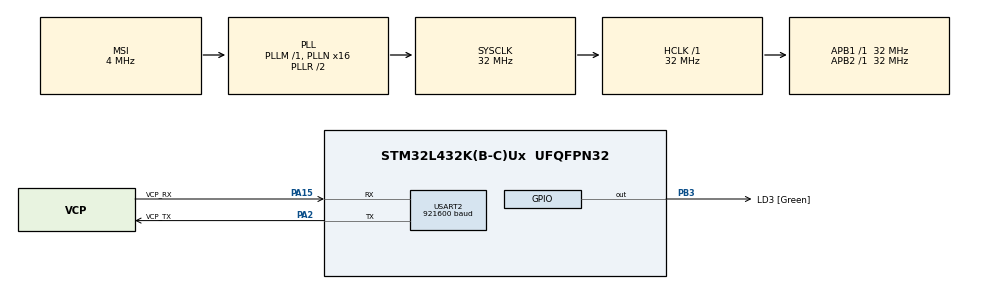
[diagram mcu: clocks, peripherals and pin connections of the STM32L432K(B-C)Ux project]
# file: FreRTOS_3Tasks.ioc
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FREERTOS.Queues01=myQueueA,16,uint16_t,0,Dynamic,NULL,NULL;myQueueB,16,uint16_t,0,Dynamic,NULL,NULL;myQueueC,16,uint16_t,0,Dynamic,NULL,NULL
FREERTOS.Tasks01=defaultTask,8,128,StartDefaultTask,Default,NULL,Dynamic,NULL,NULL;myTaskA,40,128,StartTaskA,Default,NULL,Dynamic,NULL,NULL;myTaskB,32,128,StartTaskB,Default,NULL,Dynamic,NULL,NULL;myTaskC,24,128,StartTaskC,Default,NULL,Dynamic,NULL,NULL
FREERTOS.configTOTAL_HEAP_SIZE=6000
FREERTOS.configUSE_NEWLIB_REENTRANT=1
Mcu.Family=STM32L4
Mcu.Name=STM32L432K(B-C)Ux
Mcu.Package=UFQFPN32
NVIC.PriorityGroup=NVIC_PRIORITYGROUP_4
NVIC.TIM1_BRK_TIM15_IRQn=true\:5\:0\:false\:false\:true\:true\:true\:true\:true
NVIC.TIM1_UP_TIM16_IRQn=true\:5\:0\:false\:false\:true\:true\:true\:true\:true
NVIC.TIM6_DAC_IRQn=true\:15\:0\:false\:false\:true\:false\:false\:true\:true
NVIC.TimeBase=TIM6_DAC_IRQn
NVIC.TimeBaseIP=TIM6
PA0.GPIO_Label=MCO [High speed clock in]
PA0.Mode=HSE-External-Clock-Source-for-LittleOrca
PA0.Signal=RCC_CK_IN
PA13\ (JTMS-SWDIO).GPIO_Label=SWDIO
PA13\ (JTMS-SWDIO).Mode=Serial_Wire
PA13\ (JTMS-SWDIO).Signal=SYS_JTMS-SWDIO
PA14\ (JTCK-SWCLK).GPIO_Label=SWCLK
PA14\ (JTCK-SWCLK).Mode=Serial_Wire
PA14\ (JTCK-SWCLK).Signal=SYS_JTCK-SWCLK
PA15\ (JTDI).GPIO_Label=VCP_RX
PA15\ (JTDI).Mode=Asynchronous
PA15\ (JTDI).Signal=USART2_RX
PA2.GPIO_Label=VCP_TX
PA2.Mode=Asynchronous
PA2.Signal=USART2_TX
PB3\ (JTDO-TRACESWO).GPIO_Label=LD3 [Green]
PB3\ (JTDO-TRACESWO).Signal=GPIO_Output
PC14-OSC32_IN\ (PC14).Mode=LSE-External-Oscillator
PC14-OSC32_IN\ (PC14).Signal=RCC_OSC32_IN
PC15-OSC32_OUT\ (PC15).Mode=LSE-External-Oscillator
PC15-OSC32_OUT\ (PC15).Signal=RCC_OSC32_OUT
ProjectManager.HeapSize=0x200
ProjectManager.StackSize=0x400
ProjectManager.TargetToolchain=CMake
RCC.AHBFreq_Value=32000000
RCC.APB1Freq_Value=32000000
RCC.APB1TimFreq_Value=32000000
RCC.APB2Freq_Value=32000000
RCC.APB2TimFreq_Value=32000000
RCC.CortexFreq_Value=32000000
RCC.HCLKFreq_Value=32000000
RCC.HSE_VALUE=8000000
RCC.HSI16_VALUE=16000000
RCC.HSI48_VALUE=48000000
RCC.HSI_VALUE=16000000
RCC.MSI_VALUE=4000000
RCC.PLLMUL=RCC_PLLMUL_4
RCC.PLLN=16
RCC.SYSCLKFreq_VALUE=32000000
RCC.SYSCLKSource=RCC_SYSCLKSOURCE_PLLCLK
RCC.VCOOutputFreq_Value=64000000
TIM1.Period=100-1
TIM1.Prescaler=32000-1
TIM1.RepetitionCounter=0
TIM15.Period=150-1
TIM15.Prescaler=32000-1
TIM16.Period=350-1
TIM16.Prescaler=32000-1
TIM2.Prescaler=32-1
USART2.BaudRate=921600
USART2.VirtualMode-Asynchronous=VM_ASYNC
VP_FREERTOS_VS_CMSIS_V2.Mode=CMSIS_V2
VP_SYS_VS_tim6.Mode=TIM6
VP_TIM15_VS_ClockSourceINT.Mode=Internal
VP_TIM16_VS_ClockSourceINT.Mode=Enable_Timer
VP_TIM1_VS_ClockSourceINT.Mode=Internal
VP_TIM2_VS_ClockSourceINT.Mode=Internal
board=NUCLEO-L432KC

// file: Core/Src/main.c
/* USER CODE BEGIN Header */
/**
  ******************************************************************************
  * @file           : main.c
  * @brief          : Main program body
  ******************************************************************************
  * @attention
  *
  * Copyright (c) 2023 STMicroelectronics.
  * All rights reserved.
  *
  * This software is licensed under terms that can be found in the LICENSE file
  * in the root directory of this software component.
  * If no LICENSE file comes with this software, it is provided AS-IS.
  *
  ******************************************************************************
  */
/* USER CODE END Header */
#include "main.h"
#include "cmsis_os.h"

/* USER CODE BEGIN Includes */
#include <stdio.h>
#include "tracer.h"
#include "config/tracer_config.h"
/* USER CODE END Includes */

TIM_HandleTypeDef htim1;
TIM_HandleTypeDef htim2;
TIM_HandleTypeDef htim15;
TIM_HandleTypeDef htim16;

UART_HandleTypeDef huart2;

/* Definitions for defaultTask */
osThreadId_t defaultTaskHandle;
const osThreadAttr_t defaultTask_attributes = {
  .name = "defaultTask",
  .stack_size = 128 * 4,
  .priority = (osPriority_t) osPriorityLow,
};
/* Definitions for myTaskA */
osThreadId_t myTaskAHandle;
const osThreadAttr_t myTaskA_attributes = {
  .name = "myTaskA",
  .stack_size = 128 * 4,
  .priority = (osPriority_t) osPriorityHigh,
};
/* Definitions for myTaskB */
osThreadId_t myTaskBHandle;
const osThreadAttr_t myTaskB_attributes = {
  .name = "myTaskB",
  .stack_size = 128 * 4,
  .priority = (osPriority_t) osPriorityAboveNormal,
};
/* Definitions for myTaskC */
osThreadId_t myTaskCHandle;
const osThreadAttr_t myTaskC_attributes = {
  .name = "myTaskC",
  .stack_size = 128 * 4,
  .priority = (osPriority_t) osPriorityNormal,
};
/* Definitions for myQueueA */
osMessageQueueId_t myQueueAHandle;
const osMessageQueueAttr_t myQueueA_attributes = {
  .name = "myQueueA"
};
/* Definitions for myQueueB */
osMessageQueueId_t myQueueBHandle;
const osMessageQueueAttr_t myQueueB_attributes = {
  .name = "myQueueB"
};
/* Definitions for myQueueC */
osMessageQueueId_t myQueueCHandle;
const osMessageQueueAttr_t myQueueC_attributes = {
  .name = "myQueueC"
};
/* USER CODE BEGIN PV */
// Buffer for UART
uint8_t uart_rx_buffer[32];
volatile uint8_t uart_rx_index = 0;

// Tracer task variables
osThreadId_t tracerTaskHandle;
const osThreadAttr_t tracerTask_attributes = {
  .name = "tracerTask",
  .stack_size = 128 * 4,
  .priority = (osPriority_t) osPriorityLow,
};
/* USER CODE END PV */

void SystemClock_Config(void);
static void MX_GPIO_Init(void);
static void MX_USART2_UART_Init(void);
static void MX_TIM1_Init(void);
static void MX_TIM15_Init(void);
static void MX_TIM16_Init(void);
static void MX_TIM2_Init(void);
void StartDefaultTask(void *argument);
void StartTaskA(void *argument);
void StartTaskB(void *argument);
void StartTaskC(void *argument);

/* USER CODE BEGIN 0 */
int __io_putchar(int ch) {
	while( !(USART2->ISR & USART_ISR_TXE) );
	USART2->TDR = ch;
	return ch;
}

/**
 * @brief Start UART reception in interrupt mode
 * Call this during initialization to enable command processing
 * @param None
 * @retval None
 */
void start_uart_reception(void) {
  #if MAIN_DEBUG
    const char* msg = "UART reception initialized\r\n";
    HAL_UART_Transmit(&huart2, (uint8_t*)msg, strlen(msg), HAL_MAX_DELAY);
  #endif

  HAL_UART_Receive_IT(&huart2, &uart_rx_buffer[uart_rx_index], 1);

  #if MAIN_DEBUG
    const char* msg1 = "UART receive started\r\n";
    HAL_UART_Transmit(&huart2, (uint8_t*)msg1, strlen(msg1), HAL_MAX_DELAY);
  #endif
}

/**
 * @brief Process received UART commands
 * - "DUMP" - Save trace data to flash
 * - "GET" - Retrieve trace data from flash
 */
void process_uart_command(void) {
  uart_rx_buffer[uart_rx_index] = '\0';

  #if MAIN_DEBUG
    // For debugging
    char debug_msg[50];
    snprintf(debug_msg, sizeof(debug_msg), "Received command: %s\r\n", uart_rx_buffer);
    HAL_UART_Transmit(&huart2, (uint8_t*)debug_msg, strlen(debug_msg), HAL_MAX_DELAY);
  #endif

  if (strncmp((char*)uart_rx_buffer, "TEST", 4) == 0) {
      #if MAIN_DEBUG
        const char* msg = "TEST command received successfully\r\n";
        HAL_UART_Transmit(&huart2, (uint8_t*)msg, strlen(msg), HAL_MAX_DELAY);
      #endif
  }
  // Dump command - force immediate send of trace data
  else if (strncmp((char*)uart_rx_buffer, "DUMP", 4) == 0) {
    #if MAIN_DEBUG
      const char* msg = "DUMP command: Sending all pending trace events\r\n";
      HAL_UART_Transmit(&huart2, (uint8_t*)msg, strlen(msg), HAL_MAX_DELAY);
    #endif

    tracer_send_events();
  }
  // Status command
  else if (strncmp((char*)uart_rx_buffer, "STATUS", 6) == 0) {
    #if MAIN_DEBUG
      char status_msg[150];
      snprintf(status_msg, sizeof(status_msg),
      "Trace status:\r\n"
      "Events in buffer: %lu/%d\r\n"
      "Hook calls: %lu\r\n"
      "Events sent: %lu\r\n",
      trace_count, TRACE_BUFFER_SIZE,
      trace_hook_calls, sent_events);
      HAL_UART_Transmit(&huart2, (uint8_t*)status_msg, strlen(status_msg), HAL_MAX_DELAY);
    #endif
  }

  uart_rx_index = 0;
}

/**
* @brief Function implementing the tracerTask thread.
* @param argument: Not used
* @retval None
*/
void StartTracerTask(void *argument) {
     // Small delay to let system initialize
    osDelay(500);

    #if MAIN_DEBUG
      const char* msg = "\r\n----- TRACER STARTING -----\r\n";
      HAL_UART_Transmit(&huart2, (uint8_t*)msg, strlen(msg), HAL_MAX_DELAY);

      char debug[100];
      snprintf(debug, sizeof(debug), "Tracer config: Buffer size=%d, Event size=%lu bytes\r\n",
               TRACE_BUFFER_SIZE, sizeof(trace_event_t));
      HAL_UART_Transmit(&huart2, (uint8_t*)debug, strlen(debug), HAL_MAX_DELAY);
    #endif

    // Initialize the tracer
    tracer_init();

    // Debug buffer status
    tracer_debug_buffer();

    #if MAIN_DEBUG
      // Manually log some events
      tracer_log(TRACE_EVENT_TI, 0xBEEF, NULL);
      tracer_log(TRACE_EVENT_TO, 0xBEEF, NULL);

      snprintf(debug, sizeof(debug), "Added test events. Count now: %lu\r\n", trace_count);
      HAL_UART_Transmit(&huart2, (uint8_t*)debug, strlen(debug), HAL_MAX_DELAY);

      // Clear separator before binary data starts
      msg = "\r\n----- BINARY DATA FOLLOWS -----\r\n";
      HAL_UART_Transmit(&huart2, (uint8_t*)msg, strlen(msg), HAL_MAX_DELAY);
    #endif

    tracer_send_events();

    // Main loop
    uint32_t iteration = 0;
    for(;;) {
        iteration++;

        // Process trace data - this will handle sending events
        tracer_process();

        // Every 50 iterations, force a dump all events
        if (iteration % 50 == 0) {
            #if MAIN_DEBUG
                snprintf(debug, sizeof(debug), "Forcing event dump. Count: %lu\r\n", trace_count);
                HAL_UART_Transmit(&huart2, (uint8_t*)debug, strlen(debug), HAL_MAX_DELAY);
            #endif

            tracer_send_events();
        }

        // Delay 10ms between processing cycles
        osDelay(10);
    }
}

#pragma GCC push_options
#pragma GCC optimize("O3")
void busy(uint32_t us) {
	while(us-- > 0) {
		asm("nop; nop; nop; nop;    nop; nop; nop; nop; ");
		asm("nop; nop; nop; nop;    nop; nop; nop; nop; ");
		asm("nop; nop; nop; nop;    nop; nop; nop; nop; ");
		asm("nop; nop; nop; nop;    nop;                ");
	}
}
#pragma GCC pop_options
/* USER CODE END 0 */

int main(void)
{

  /* MCU Configuration--------------------------------------------------------*/

  /* Reset of all peripherals, Initializes the Flash interface and the Systick. */
  HAL_Init();

  /* Configure the system clock */
  SystemClock_Config();

  /* Initialize all configured peripherals */
  MX_GPIO_Init();
  MX_USART2_UART_Init();
  MX_TIM1_Init();
  MX_TIM15_Init();
  MX_TIM16_Init();
  MX_TIM2_Init();
  /* USER CODE BEGIN 2 */

  HAL_TIM_Base_Start(&htim2);
  start_uart_reception();
  /* USER CODE END 2 */

  /* Init scheduler */
  osKernelInitialize();

  /* Create the queue(s) */
  /* creation of myQueueA */
  myQueueAHandle = osMessageQueueNew (16, sizeof(uint16_t), &myQueueA_attributes);

  /* creation of myQueueB */
  myQueueBHandle = osMessageQueueNew (16, sizeof(uint16_t), &myQueueB_attributes);

  /* creation of myQueueC */
  myQueueCHandle = osMessageQueueNew (16, sizeof(uint16_t), &myQueueC_attributes);

  /* Create the thread(s) */
  /* creation of defaultTask */
  defaultTaskHandle = osThreadNew(StartDefaultTask, NULL, &defaultTask_attributes);

  /* creation of myTaskA */
  myTaskAHandle = osThreadNew(StartTaskA, NULL, &myTaskA_attributes);

  /* creation of myTaskB */
  myTaskBHandle = osThreadNew(StartTaskB, NULL, &myTaskB_attributes);

  /* creation of myTaskC */
  myTaskCHandle = osThreadNew(StartTaskC, NULL, &myTaskC_attributes);

  /* USER CODE BEGIN RTOS_THREADS */
  /* add threads, ... */
  tracerTaskHandle = osThreadNew(StartTracerTask, NULL, &tracerTask_attributes);
  if (tracerTaskHandle == NULL) {
    Error_Handler();
  }
  /* USER CODE END RTOS_THREADS */

  /* Start scheduler */
  osKernelStart();

  /* We should never get here as control is now taken by the scheduler */

  /* Infinite loop */
  while (1)
  {

  }
}

void SystemClock_Config(void)
{
  RCC_OscInitTypeDef RCC_OscInitStruct = {0};
  RCC_ClkInitTypeDef RCC_ClkInitStruct = {0};

  /** Configure the main internal regulator output voltage
  */
  if (HAL_PWREx_ControlVoltageScaling(PWR_REGULATOR_VOLTAGE_SCALE1) != HAL_OK)
  {
    Error_Handler();
  }

  /** Configure LSE Drive Capability
  */
  HAL_PWR_EnableBkUpAccess();
  __HAL_RCC_LSEDRIVE_CONFIG(RCC_LSEDRIVE_LOW);

  /** Initializes the RCC Oscillators according to the specified parameters
  * in the RCC_OscInitTypeDef structure.
  */
  RCC_OscInitStruct.OscillatorType = RCC_OSCILLATORTYPE_LSE|RCC_OSCILLATORTYPE_MSI;
  RCC_OscInitStruct.LSEState = RCC_LSE_ON;
  RCC_OscInitStruct.MSIState = RCC_MSI_ON;
  RCC_OscInitStruct.MSICalibrationValue = 0;
  RCC_OscInitStruct.MSIClockRange = RCC_MSIRANGE_6;
  RCC_OscInitStruct.PLL.PLLState = RCC_PLL_ON;
  RCC_OscInitStruct.PLL.PLLSource = RCC_PLLSOURCE_MSI;
  RCC_OscInitStruct.PLL.PLLM = 1;
  RCC_OscInitStruct.PLL.PLLN = 16;
  RCC_OscInitStruct.PLL.PLLP = RCC_PLLP_DIV7;
  RCC_OscInitStruct.PLL.PLLQ = RCC_PLLQ_DIV2;
  RCC_OscInitStruct.PLL.PLLR = RCC_PLLR_DIV2;
  if (HAL_RCC_OscConfig(&RCC_OscInitStruct) != HAL_OK)
  {
    Error_Handler();
  }

  /** Initializes the CPU, AHB and APB buses clocks
  */
  RCC_ClkInitStruct.ClockType = RCC_CLOCKTYPE_HCLK|RCC_CLOCKTYPE_SYSCLK
                              |RCC_CLOCKTYPE_PCLK1|RCC_CLOCKTYPE_PCLK2;
  RCC_ClkInitStruct.SYSCLKSource = RCC_SYSCLKSOURCE_PLLCLK;
  RCC_ClkInitStruct.AHBCLKDivider = RCC_SYSCLK_DIV1;
  RCC_ClkInitStruct.APB1CLKDivider = RCC_HCLK_DIV1;
  RCC_ClkInitStruct.APB2CLKDivider = RCC_HCLK_DIV1;

  if (HAL_RCC_ClockConfig(&RCC_ClkInitStruct, FLASH_LATENCY_1) != HAL_OK)
  {
    Error_Handler();
  }

  /** Enable MSI Auto calibration
  */
  HAL_RCCEx_EnableMSIPLLMode();
}

static void MX_TIM1_Init(void)
{

  TIM_ClockConfigTypeDef sClockSourceConfig = {0};
  TIM_MasterConfigTypeDef sMasterConfig = {0};

  htim1.Instance = TIM1;
  htim1.Init.Prescaler = 32000-1;
  htim1.Init.CounterMode = TIM_COUNTERMODE_UP;
  htim1.Init.Period = 100-1;
  htim1.Init.ClockDivision = TIM_CLOCKDIVISION_DIV1;
  htim1.Init.RepetitionCounter = 0;
  htim1.Init.AutoReloadPreload = TIM_AUTORELOAD_PRELOAD_DISABLE;
  if (HAL_TIM_Base_Init(&htim1) != HAL_OK)
  {
    Error_Handler();
  }
  sClockSourceConfig.ClockSource = TIM_CLOCKSOURCE_INTERNAL;
  if (HAL_TIM_ConfigClockSource(&htim1, &sClockSourceConfig) != HAL_OK)
  {
    Error_Handler();
  }
  sMasterConfig.MasterOutputTrigger = TIM_TRGO_RESET;
  sMasterConfig.MasterOutputTrigger2 = TIM_TRGO2_RESET;
  sMasterConfig.MasterSlaveMode = TIM_MASTERSLAVEMODE_DISABLE;
  if (HAL_TIMEx_MasterConfigSynchronization(&htim1, &sMasterConfig) != HAL_OK)
  {
    Error_Handler();
  }

}

static void MX_TIM2_Init(void)
{

  TIM_ClockConfigTypeDef sClockSourceConfig = {0};
  TIM_MasterConfigTypeDef sMasterConfig = {0};

  htim2.Instance = TIM2;
  htim2.Init.Prescaler = 32-1;
  htim2.Init.CounterMode = TIM_COUNTERMODE_UP;
  htim2.Init.Period = 4294967295;
  htim2.Init.ClockDivision = TIM_CLOCKDIVISION_DIV1;
  htim2.Init.AutoReloadPreload = TIM_AUTORELOAD_PRELOAD_DISABLE;
  if (HAL_TIM_Base_Init(&htim2) != HAL_OK)
  {
    Error_Handler();
  }
  sClockSourceConfig.ClockSource = TIM_CLOCKSOURCE_INTERNAL;
  if (HAL_TIM_ConfigClockSource(&htim2, &sClockSourceConfig) != HAL_OK)
  {
    Error_Handler();
  }
  sMasterConfig.MasterOutputTrigger = TIM_TRGO_RESET;
  sMasterConfig.MasterSlaveMode = TIM_MASTERSLAVEMODE_DISABLE;
  if (HAL_TIMEx_MasterConfigSynchronization(&htim2, &sMasterConfig) != HAL_OK)
  {
    Error_Handler();
  }

}

static void MX_TIM15_Init(void)
{

  TIM_ClockConfigTypeDef sClockSourceConfig = {0};
  TIM_MasterConfigTypeDef sMasterConfig = {0};

  htim15.Instance = TIM15;
  htim15.Init.Prescaler = 32000-1;
  htim15.Init.CounterMode = TIM_COUNTERMODE_UP;
  htim15.Init.Period = 150-1;
  htim15.Init.ClockDivision = TIM_CLOCKDIVISION_DIV1;
  htim15.Init.RepetitionCounter = 0;
  htim15.Init.AutoReloadPreload = TIM_AUTORELOAD_PRELOAD_DISABLE;
  if (HAL_TIM_Base_Init(&htim15) != HAL_OK)
  {
    Error_Handler();
  }
  sClockSourceConfig.ClockSource = TIM_CLOCKSOURCE_INTERNAL;
  if (HAL_TIM_ConfigClockSource(&htim15, &sClockSourceConfig) != HAL_OK)
  {
    Error_Handler();
  }
  sMasterConfig.MasterOutputTrigger = TIM_TRGO_RESET;
  sMasterConfig.MasterSlaveMode = TIM_MASTERSLAVEMODE_DISABLE;
  if (HAL_TIMEx_MasterConfigSynchronization(&htim15, &sMasterConfig) != HAL_OK)
  {
    Error_Handler();
  }

}

static void MX_TIM16_Init(void)
{

  htim16.Instance = TIM16;
  htim16.Init.Prescaler = 32000-1;
  htim16.Init.CounterMode = TIM_COUNTERMODE_UP;
  htim16.Init.Period = 350-1;
  htim16.Init.ClockDivision = TIM_CLOCKDIVISION_DIV1;
  htim16.Init.RepetitionCounter = 0;
  htim16.Init.AutoReloadPreload = TIM_AUTORELOAD_PRELOAD_DISABLE;
  if (HAL_TIM_Base_Init(&htim16) != HAL_OK)
  {
    Error_Handler();
  }

}

static void MX_USART2_UART_Init(void)
{

  huart2.Instance = USART2;
  huart2.Init.BaudRate = 921600;
  huart2.Init.WordLength = UART_WORDLENGTH_8B;
  huart2.Init.StopBits = UART_STOPBITS_1;
  huart2.Init.Parity = UART_PARITY_NONE;
  huart2.Init.Mode = UART_MODE_TX_RX;
  huart2.Init.HwFlowCtl = UART_HWCONTROL_NONE;
  huart2.Init.OverSampling = UART_OVERSAMPLING_16;
  huart2.Init.OneBitSampling = UART_ONE_BIT_SAMPLE_DISABLE;
  huart2.AdvancedInit.AdvFeatureInit = UART_ADVFEATURE_NO_INIT;
  if (HAL_UART_Init(&huart2) != HAL_OK)
  {
    Error_Handler();
  }

}

static void MX_GPIO_Init(void)
{
  GPIO_InitTypeDef GPIO_InitStruct = {0};

  /* GPIO Ports Clock Enable */
  __HAL_RCC_GPIOC_CLK_ENABLE();
  __HAL_RCC_GPIOA_CLK_ENABLE();
  __HAL_RCC_GPIOB_CLK_ENABLE();

  /*Configure GPIO pin Output Level */
  HAL_GPIO_WritePin(LD3_GPIO_Port, LD3_Pin, GPIO_PIN_RESET);

  /*Configure GPIO pin : LD3_Pin */
  GPIO_InitStruct.Pin = LD3_Pin;
  GPIO_InitStruct.Mode = GPIO_MODE_OUTPUT_PP;
  GPIO_InitStruct.Pull = GPIO_NOPULL;
  GPIO_InitStruct.Speed = GPIO_SPEED_FREQ_LOW;
  HAL_GPIO_Init(LD3_GPIO_Port, &GPIO_InitStruct);

}

void StartDefaultTask(void *argument)
{
  for(;;)
  {
    osDelay(1);
  }
}

void StartTaskA(void *argument)
{
  /* USER CODE BEGIN StartTaskA */
  #if MAIN_DEBUG
    /* Force a trace event for testing */
    tracer_TASK_SWITCHED_IN(1); // Manually call with task ID 1

    /* Print debug */
    char debug[50];
    snprintf(debug, sizeof(debug), "TaskA: Called trace hook manually\r\n");
    HAL_UART_Transmit(&huart2, (uint8_t*)debug, strlen(debug), HAL_MAX_DELAY);
  #endif

  /* Infinite loop */
	  HAL_TIM_Base_Start_IT(&htim1);
  for(;;)
  {
	  char str[2];
	  osStatus_t status = osMessageQueueGet(myQueueAHandle, &str, 0, 1000);
	  if(status!=osOK) {
		  Error_Handler();
	  }
	  busy(20000);
  }
  /* USER CODE END StartTaskA */
}

void StartTaskB(void *argument)
{
  /* USER CODE BEGIN StartTaskB */
  #if MAIN_DEBUG
    /* Force a trace event for testing */
    tracer_TASK_SWITCHED_IN(2); // Manually call with task ID 1

    /* Print debug */
    char debug[50];
    snprintf(debug, sizeof(debug), "TaskB: Called trace hook manually\r\n");
    HAL_UART_Transmit(&huart2, (uint8_t*)debug, strlen(debug), HAL_MAX_DELAY);
  #endif

  /* Infinite loop */
	  HAL_TIM_Base_Start_IT(&htim15);
  for(;;)
  {
	  char str[2];
	  osStatus_t status = osMessageQueueGet(myQueueBHandle, &str, 0, 1000);
	  if(status!=osOK) {
		  Error_Handler();
	  }
	  busy(40000);
  }
  /* USER CODE END StartTaskB */
}

void StartTaskC(void *argument)
{
  /* USER CODE BEGIN StartTaskC */
  #if MAIN_DEBUG
    /* Force a trace event for testing */
    tracer_TASK_SWITCHED_IN(3); // Manually call with task ID 1

    /* Print debug */
    char debug[50];
    snprintf(debug, sizeof(debug), "TaskC: Called trace hook manually\r\n");
    HAL_UART_Transmit(&huart2, (uint8_t*)debug, strlen(debug), HAL_MAX_DELAY);
  #endif

  /* Infinite loop */
	  HAL_TIM_Base_Start_IT(&htim16);
  for(;;)
  {
	  char str[2];
	  osStatus_t status = osMessageQueueGet(myQueueCHandle, &str, 0, 1000);
	  if(status!=osOK) {
		  Error_Handler();
	  }
	  busy(100000);
  }
  /* USER CODE END StartTaskC */
}

void HAL_TIM_PeriodElapsedCallback(TIM_HandleTypeDef *htim)
{
  if (htim->Instance == TIM6) {
    HAL_IncTick();
  }
  /* USER CODE BEGIN Callback 1 */
  if (htim->Instance == TIM1) {
    osStatus status = osMessageQueuePut(myQueueAHandle, "A", 0, 0);
    if(status!=osOK) {
    	Error_Handler();
    }
  }
  if (htim->Instance == TIM15) {
	    osStatus status = osMessageQueuePut(myQueueBHandle, "B", 0, 0);
	    if(status!=osOK) {
	    	Error_Handler();
	    }
  }
  if (htim->Instance == TIM16) {
	    osStatus status = osMessageQueuePut(myQueueCHandle, "C", 0, 0);
	    if(status!=osOK) {
	    	Error_Handler();
	    }
  }
  /* USER CODE END Callback 1 */
}

/**
 * @brief UART reception callback
 * This is called by the HAL when a character is received over UART
 * @param huart: UART handle
 */
void HAL_UART_RxCpltCallback(UART_HandleTypeDef *huart) {
  if (huart->Instance == USART2) {
    #if MAIN_DEBUG
      const char* msg = "Character received\r\n";
      HAL_UART_Transmit(&huart2, (uint8_t*)msg, strlen(msg), HAL_MAX_DELAY);
    #endif

      if (uart_rx_buffer[uart_rx_index] == '\r' || uart_rx_buffer[uart_rx_index] == '\n') {
          if (uart_rx_index > 0) {
              process_uart_command();
          }
      }
      else {
          uart_rx_index++;

          // Check for buffer overflow
          if (uart_rx_index >= sizeof(uart_rx_buffer) - 1) {
              uart_rx_index = 0;  // Reset buffer
          }
      }

      HAL_UART_Receive_IT(&huart2, &uart_rx_buffer[uart_rx_index], 1);
  }
}

/**
  * @brief  UART transmission complete callback
  * @param  huart: UART handle
  * @retval None
  */
void HAL_UART_TxCpltCallback(UART_HandleTypeDef *huart) {
  if (huart->Instance == USART2) {
    #if MAIN_DEBUG
      const char* cb_msg = "TX complete callback\r\n";
      HAL_UART_Transmit(&huart2, (uint8_t*)cb_msg, strlen(cb_msg), HAL_MAX_DELAY);
    #endif

    // Mark UART as free for tracer
    extern volatile uint8_t uart_busy;
    uart_busy = 0;
  }
}

void Error_Handler(void)
{
  /* USER CODE BEGIN Error_Handler_Debug */
  /* User can add his own implementation to report the HAL error return state */
  #if MAIN_DEBUG
    const char* msg = "ERROR: System error occurred!\r\n";
    HAL_UART_Transmit(&huart2, (uint8_t*)msg, strlen(msg), HAL_MAX_DELAY);
  #endif

  // Send all remaining trace data
  tracer_process();

  __disable_irq();
  while (1)
  {
  }
  /* USER CODE END Error_Handler_Debug */
}
